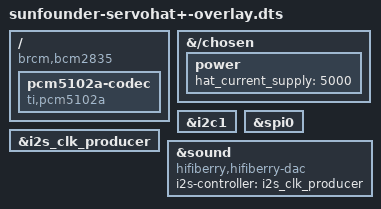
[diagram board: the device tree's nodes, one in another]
/dts-v1/;
/plugin/;

/ {
	compatible = "brcm,bcm2835";

	fragment@0 {
		target-path = "/chosen";
		__overlay__ {
			power: power {
				hat_current_supply = <5000>;
			};
		};
	};
	fragment@1 {
		target = <&i2c1>;
		__overlay__ {
			status = "okay";
		};
	};
	fragment@2 {
		target = <&spi0>;
		__overlay__ {
			status = "okay";
		};
	};
	fragment@3 {
		target = <&i2s_clk_producer>;
		__overlay__ {
			status = "okay";
		};
	};
	fragment@4 {
		target-path = "/";
		__overlay__ {
			pcm5102a-codec {
				compatible = "ti,pcm5102a";
				status = "okay";
			};
		};
	};
	fragment@5 {
		target = <&sound>;
		__overlay__ {
			compatible = "hifiberry,hifiberry-dac";
			i2s-controller = <&i2s_clk_producer>;
			status = "okay";
		};
	};

};
